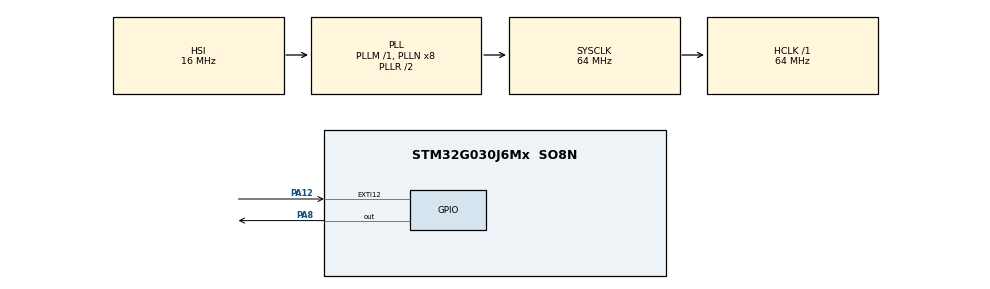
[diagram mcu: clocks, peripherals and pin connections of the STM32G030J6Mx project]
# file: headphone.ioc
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Mcu.Family=STM32G0
Mcu.Name=STM32G030J6Mx
Mcu.Package=SO8N
NRST__PA0__PA1__PA2.StandardMode=true
NVIC.EXTI4_15_IRQn=true\:0\:0\:false\:false\:true\:true\:true\:true
NVIC.TIM14_IRQn=true\:0\:0\:false\:false\:true\:true\:true\:true
NVIC.TIM1_BRK_UP_TRG_COM_IRQn=true\:0\:0\:false\:false\:true\:true\:true\:true
PA12\ [PA10].GPIO_ModeDefaultEXTI=GPIO_MODE_IT_FALLING
PA12\ [PA10].GPIO_PuPd=GPIO_PULLUP
PA12\ [PA10].Signal=GPXTI12
PA13.Mode=Serial_Wire
PA13.Signal=SYS_SWDIO
PA14-BOOT0.Mode=Serial_Wire
PA14-BOOT0.Signal=SYS_SWCLK
PA14-BOOT0__PA15__PB5__PB6.StandardMode=true
PA8.GPIO_PuPd=GPIO_PULLUP
PA8.GPIO_Speed=GPIO_SPEED_FREQ_HIGH
PA8.Signal=GPIO_Output
PB0__PB1__PA8__PA11\ [PA9].StandardMode=true
PC14-OSC32_IN\ (PC14)__PB7__PB8__PB9.StandardMode=true
ProjectManager.HeapSize=0x200
ProjectManager.StackSize=0x400
ProjectManager.TargetToolchain=MDK-ARM V5.32
RCC.ADCFreq_Value=64000000
RCC.AHBFreq_Value=64000000
RCC.CortexFreq_Value=64000000
RCC.EXTERNAL_CLOCK_VALUE=12288000
RCC.HCLKFreq_Value=64000000
RCC.HSE_VALUE=8000000
RCC.HSI_VALUE=16000000
RCC.LSE_VALUE=32768
RCC.SYSCLKFreq_VALUE=64000000
RCC.SYSCLKSource=RCC_SYSCLKSOURCE_PLLCLK
RCC.VCOOutputFreq_Value=128000000
TIM1.AutoReloadPreload=TIM_AUTORELOAD_PRELOAD_ENABLE
TIM1.Period=21
TIM1.Prescaler=0
TIM1.RepetitionCounter=21
TIM1.TIM_MasterSlaveMode=TIM_MASTERSLAVEMODE_ENABLE
TIM14.Period=1000
TIM14.Prescaler=63
VP_TIM14_VS_ClockSourceINT.Mode=Enable_Timer
VP_TIM14_VS_OPM.Mode=OPM_bit
VP_TIM1_VS_ClockSourceINT.Mode=Internal
board=custom

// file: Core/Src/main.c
/* USER CODE BEGIN Header */
/**
  ******************************************************************************
  * @file           : main.c
  * @brief          : Main program body
  ******************************************************************************
  * @attention
  *
  * <h2><center>&copy; Copyright (c) 2023 STMicroelectronics.
  * All rights reserved.</center></h2>
  *
  * This software component is licensed by ST under BSD 3-Clause license,
  * the "License"; You may not use this file except in compliance with the
  * License. You may obtain a copy of the License at:
  *                        opensource.org/licenses/BSD-3-Clause
  *
  ******************************************************************************
  */
/* USER CODE END Header */
#include "main.h"
#include "tim.h"
#include "gpio.h"

/* USER CODE BEGIN Includes */
#include "EventRecorder.h"

/* USER CODE END Includes */

void SystemClock_Config(void);

/* USER CODE BEGIN 0 */
extern void main_loop(void);
/* USER CODE END 0 */

int main(void)
{
  /* USER CODE BEGIN 1 */
    EventRecorderInitialize(EventRecordAll, 1U);
    EventRecorderStart();

    EventStartA(0);
    EventStopA(0);
  /* USER CODE END 1 */

  /* MCU Configuration--------------------------------------------------------*/

  /* Reset of all peripherals, Initializes the Flash interface and the Systick. */
  HAL_Init();

  /* Configure the system clock */
  SystemClock_Config();

  /* Initialize all configured peripherals */
  MX_GPIO_Init();
  MX_TIM1_Init();
  MX_TIM14_Init();
  /* USER CODE BEGIN 2 */
  main_loop();
  /* USER CODE END 2 */

  /* Infinite loop */
  while (1)
  {

  }
}

void SystemClock_Config(void)
{
  RCC_OscInitTypeDef RCC_OscInitStruct = {0};
  RCC_ClkInitTypeDef RCC_ClkInitStruct = {0};

  /** Configure the main internal regulator output voltage
  */
  HAL_PWREx_ControlVoltageScaling(PWR_REGULATOR_VOLTAGE_SCALE1);

  /** Initializes the RCC Oscillators according to the specified parameters
  * in the RCC_OscInitTypeDef structure.
  */
  RCC_OscInitStruct.OscillatorType = RCC_OSCILLATORTYPE_HSI;
  RCC_OscInitStruct.HSIState = RCC_HSI_ON;
  RCC_OscInitStruct.HSIDiv = RCC_HSI_DIV1;
  RCC_OscInitStruct.HSICalibrationValue = RCC_HSICALIBRATION_DEFAULT;
  RCC_OscInitStruct.PLL.PLLState = RCC_PLL_ON;
  RCC_OscInitStruct.PLL.PLLSource = RCC_PLLSOURCE_HSI;
  RCC_OscInitStruct.PLL.PLLM = RCC_PLLM_DIV1;
  RCC_OscInitStruct.PLL.PLLN = 8;
  RCC_OscInitStruct.PLL.PLLP = RCC_PLLP_DIV2;
  RCC_OscInitStruct.PLL.PLLR = RCC_PLLR_DIV2;
  if (HAL_RCC_OscConfig(&RCC_OscInitStruct) != HAL_OK)
  {
    Error_Handler();
  }

  /** Initializes the CPU, AHB and APB buses clocks
  */
  RCC_ClkInitStruct.ClockType = RCC_CLOCKTYPE_HCLK|RCC_CLOCKTYPE_SYSCLK
                              |RCC_CLOCKTYPE_PCLK1;
  RCC_ClkInitStruct.SYSCLKSource = RCC_SYSCLKSOURCE_PLLCLK;
  RCC_ClkInitStruct.AHBCLKDivider = RCC_SYSCLK_DIV1;
  RCC_ClkInitStruct.APB1CLKDivider = RCC_HCLK_DIV1;

  if (HAL_RCC_ClockConfig(&RCC_ClkInitStruct, FLASH_LATENCY_2) != HAL_OK)
  {
    Error_Handler();
  }
}

void Error_Handler(void)
{
  __disable_irq();
  while (1)
  {
  }
}
